VERSION "wican-gen-inhibit-diag schema 8"

NS_ :

BS_:

BU_: WICAN

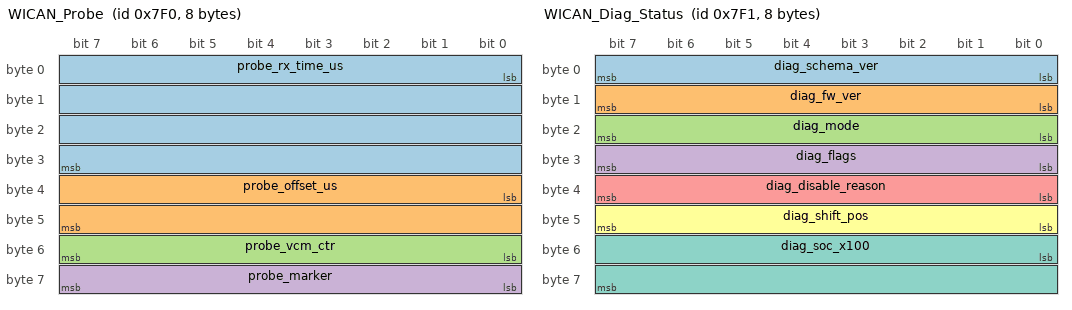
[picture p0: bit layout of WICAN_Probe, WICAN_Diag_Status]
BO_ 2032 WICAN_Probe: 8 WICAN
 SG_ probe_rx_time_us : 0|32@1+ (1,0) [0|4294967295] "us" Vector__XXX
 SG_ probe_offset_us : 32|16@1+ (1,0) [0|65535] "us" Vector__XXX
 SG_ probe_vcm_ctr : 48|8@1+ (1,0) [0|15] "" Vector__XXX
 SG_ probe_marker : 56|8@1+ (1,0) [90|90] "" Vector__XXX

BO_ 2033 WICAN_Diag_Status: 8 WICAN
 SG_ diag_schema_ver : 0|8@1+ (1,0) [0|255] "" Vector__XXX
 SG_ diag_fw_ver : 8|8@1+ (1,0) [0|255] "" Vector__XXX
 SG_ diag_mode : 16|8@1+ (1,0) [0|4] "" Vector__XXX
 SG_ diag_flags : 24|8@1+ (1,0) [0|255] "" Vector__XXX
 SG_ diag_disable_reason : 32|8@1+ (1,0) [0|2] "" Vector__XXX
 SG_ diag_shift_pos : 40|8@1+ (1,0) [0|255] "" Vector__XXX
 SG_ diag_soc_x100 : 48|16@1+ (0.01,0) [0|100] "%" Vector__XXX

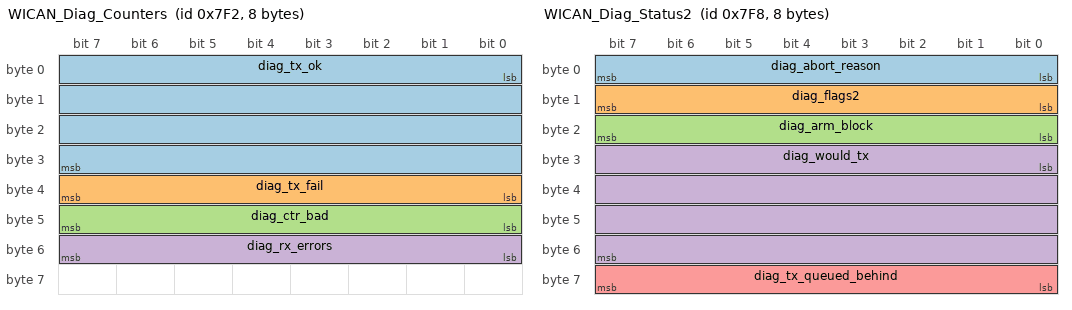
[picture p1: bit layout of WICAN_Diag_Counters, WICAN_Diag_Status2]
BO_ 2034 WICAN_Diag_Counters: 8 WICAN
 SG_ diag_tx_ok : 0|32@1+ (1,0) [0|4294967295] "" Vector__XXX
 SG_ diag_tx_fail : 32|8@1+ (1,0) [0|255] "" Vector__XXX
 SG_ diag_ctr_bad : 40|8@1+ (1,0) [0|255] "" Vector__XXX
 SG_ diag_rx_errors : 48|8@1+ (1,0) [0|255] "" Vector__XXX

BO_ 2040 WICAN_Diag_Status2: 8 WICAN
 SG_ diag_abort_reason : 0|8@1+ (1,0) [0|255] "" Vector__XXX
 SG_ diag_flags2 : 8|8@1+ (1,0) [0|255] "" Vector__XXX
 SG_ diag_arm_block : 16|8@1+ (1,0) [0|255] "" Vector__XXX
 SG_ diag_would_tx : 24|32@1+ (1,0) [0|4294967295] "" Vector__XXX
 SG_ diag_tx_queued_behind : 56|8@1+ (1,0) [0|255] "" Vector__XXX

BO_ 2041 WICAN_Diag_Skips: 8 WICAN
 SG_ diag_skips_withdrawn : 0|32@1+ (1,0) [0|4294967295] "" Vector__XXX
 SG_ diag_skips_late : 32|32@1+ (1,0) [0|4294967295] "" Vector__XXX

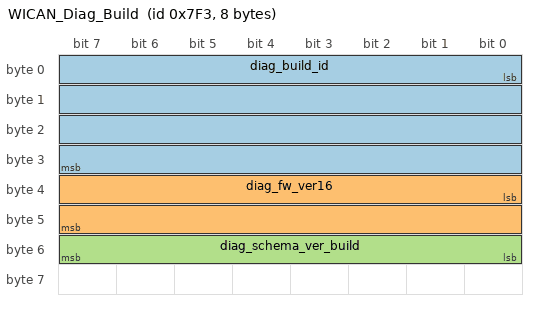
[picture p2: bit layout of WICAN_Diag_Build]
BO_ 2035 WICAN_Diag_Build: 8 WICAN
 SG_ diag_build_id : 0|32@1+ (1,0) [0|4294967295] "" Vector__XXX
 SG_ diag_fw_ver16 : 32|16@1+ (1,0) [0|65535] "" Vector__XXX
 SG_ diag_schema_ver_build : 48|8@1+ (1,0) [0|255] "" Vector__XXX

CM_ BO_ 2032 "WiCAN gen-inhibit RESPOND timing probe. 0x7F0, DLC 8, one per received 0x051 in RESPOND (diag_mode 2), due probe_offset_us after it. Not a diag frame and not versioned by diag_schema_ver. Layout published 2026-10-12 (user); source of truth: wican_diag_schema.md, section 0x7F0.";
CM_ SG_ 2032 probe_rx_time_us "The device's receive time of the 0x051 this probe answers: its own esp_timer microsecond clock, low 32 bits; wraps about every 71.6 min.";
CM_ SG_ 2032 probe_offset_us "The response delay setting the probe was scheduled with.";
CM_ SG_ 2032 probe_vcm_ctr "Rolling counter (0x051 B5 low nibble) of the most recent 0x051 received with DLC >= 6, the one this probe answers. A probe is late when this is older than the newest 0x051 counter on the wire when the probe appears.";
CM_ SG_ 2032 probe_marker "Constant 0x5A.";
CM_ BO_ 2033 "WiCAN gen-inhibit self-telemetry, STATUS. 0x7F1, DLC 8, ~1 Hz, transmitted by the WiCAN itself (not a truck ECU) so an Android/laptop log is self-documenting. 0x7F1-0x7F3 are in the 0x7Fx range nothing on the truck consumes (same rationale as the 0x7F0 timing probe). ID ALLOCATION ON THIS TRUCK: WiCAN 0x7F1-0x7F3 and 0x7F8; charge interposer 0x7F4-0x7F7 (vtrux-interposer-diag.dbc). Both devices transmit on the powertrain bus and may be fitted together, so the ranges are disjoint by agreement -- schema 4 first shipped its fourth page on 0x7F4 and had to be moved. WiCAN gained 0x7F9 (SKIPS) at schema 5, so its range is now 0x7F1-0x7F3 plus 0x7F8-0x7F9. Take the next page from 0x7FA upward and record it in both schema docs. Forward-engineered, authoritative by design; keep this DBC, the schema doc, and the firmware in lockstep via diag_schema_ver.";
CM_ BO_ 2034 "WiCAN gen-inhibit self-telemetry, COUNTERS. 0x7F2, DLC 8, ~1 Hz. Inhibit transmit totals and error counts.";
CM_ BO_ 2041 "WiCAN gen-inhibit self-telemetry, SKIPS. 0x7F9, DLC 8, added at schema 5 (spec 5.2 item 5, section 10). Skipped inhibit frames since the device was armed, split by kind. WHY THIS PAGE EXISTS: a skipped inhibit means the generator inverter acted on the VCM's real torque command for one cycle, and before schema 5 the only trace of that in a CAN log was diag_abort_reason 15 -- the trip that three skips within one second cause. An isolated skip left no trace at all, and nobody is connected to the HTTP status page during a drive. The rest of the transmit scheduler's counters are deliberately NOT here: they are on the status page only (spec section 11), because lost telemetry already shows in a CAN log as a gap in these pages themselves.";
CM_ SG_ 2041 diag_skips_withdrawn "Inhibit frames withdrawn at their deadline -- removed before reaching the wire, so the inverter never saw ours. Since arming; resets to 0 on a re-arm, so differencing across an arm boundary can step negative.";
CM_ SG_ 2041 diag_skips_late "Inhibit frames that went out late, or may have. The device cannot tell these apart: the TWAI driver reports an aborted frame and a real transmission identically, as TX_SUCCESS with msgs_to_tx falling to 0 (169 of 169 measured). Counted separately from withdrawn because a reader deciding whether our frame reached the bus needs to know which happened, and summing them would destroy exactly that. Since arming.";
CM_ BO_ 2035 "WiCAN gen-inhibit self-telemetry, BUILD. 0x7F3, DLC 8, ~1 Hz. Names the running binary by the first four bytes of its image hash (schema 8, port step 0c), for matching a log to one image file.";
CM_ SG_ 2033 diag_schema_ver "On-wire schema version. A decoder holding a different DBC version should flag a mismatch rather than trust the fields. Bump when any layout changes.";
CM_ SG_ 2033 diag_fw_ver "Behaviour/capability revision, hand-bumped when correctly parsed values must be interpreted differently or a behaviour someone would gate on changes. The name is historical; it stays, by hand, until stage (b) of the shared-code port retires it (user, 2026-10-25). diag_schema_ver governs layout and which pages exist. Rev table in the schema doc.";
CM_ SG_ 2033 diag_flags "bit0 disabled, bit1 bus_on (the CONTROLLER is running: set only while twai_get_status_info() reports TWAI_STATE_RUNNING, clear when it is stopped, bus-off or recovering, and clear when the driver is not installed -- spec 11. MEANING CHANGED AT SCHEMA 6: through schema 5 this bit reported only that the TWAI driver was installed. On the wire the change is not visible in practice: a controller that is not running transmits nothing, so a bus-off shows in a CAN log as a gap in the diag pages under either meaning. The difference shows on the status page, where on 2026-10-06 bus_on read true through 42.1 s of bus-off. The schema bump exists so that a decoder does not attach the new meaning to a schema-5 log. Check diag_schema_ver before reading it), bit2 bus_ours, bit3 autoarm_build, bit4 shutdown_suppressed (0x051 B0 = 0x10; live, non-latching, spec 6.3), bit5 inhibit_live (the spec 7 arm gate is satisfied and the inhibit is live; on its own it does not mean the inhibitor is transmitting: it stays set while armed but silent, at a key-off (bit6 clear) and during a 6.3 shutdown suppression (bit4 set); a 0x051 is sent only with bits 5 and 6 set and bits 0, 4 and 7 clear; distinct from diag_mode 3, which is only what was requested), bit6 key_on (0x592 B0 bit4 reading on AND fresh; spec 7.1 gates transmission on it, and 0 covers both a key-off and a bus with no 0x592 at all -- bit1/bit2 separate those), bit7 abort_latched (a spec 7 abort has stood the device down; it stays armed and keeps sending diag, and a key-off-to-key-on clears it).";
CM_ BO_ 2040 "WiCAN gen-inhibit self-telemetry, STATUS2. 0x7F8, DLC 8, added at schema 4 (review B1). Carries what a PASSIVE dry run needs to be readable: WHICH section 7 trip latched (diag_flags on 0x7F1 says only that one did), why the inhibit is not live, the spec 6.2 SoC-valid marker, and the would-transmit count. Appended as a fourth frame rather than repacking 0x7F1, which is full to B7 -- so a schema-3 decoder reads 0x7F1-0x7F3 unchanged and simply does not see this page.";
CM_ SG_ 2040 diag_abort_reason "Which spec 7 trip latched the inhibit off. gi_abort_t in gen_inhibit_core.h, in order -- APPEND ONLY, since reordering silently changes what every recorded log means. 14 tx_late is RETIRED (2026-09-27, spec 7 trip 7 amended): nothing sets it any more, and it is kept because captures from before that date carry it. 15 skips_3_in_1s replaced it -- a single late or withdrawn inhibit frame is now a counted skip, and three within one second trip.";
CM_ SG_ 2040 diag_arm_block "Why the inhibit is not live. 0 means the gate is satisfied. gi_block_t in gen_inhibit_core.h, append only.";
CM_ SG_ 2040 diag_flags2 "bit0 soc_valid (spec 6.2: the main contactors have reported closed and the BMS has not slept since, so 0x411 readings count), bit1 soc_since_valid (an 0x411 has arrived since the marker was set), bit2 tx_pending (an inhibit frame was outstanding when this page was built), bit3 emit_refused (a code path tried to transmit a real 0x051 from a mode that must not -- ALWAYS 0; non-zero is a firmware bug, not a bus event).";
CM_ SG_ 2040 diag_would_tx "PASSIVE (diag_mode 4) counts one of these wherever INHIBIT would have transmitted, since the last arm (reset on every arm, like diag_tx_ok, from schema 7; through schema 6 it counted since boot). Deliberately NOT folded into diag_tx_ok: a decoder that ignored diag_mode would otherwise read a dry run as a drive in which the device transmitted thousands of times. The two are mutually exclusive by mode, which is a property worth being able to check.";
CM_ SG_ 2040 diag_tx_queued_behind "Spec 5's hazard, counted: inhibit frames queued into the controller behind a frame of ours that had not finished. Saturates at 255. Any non-zero value on the bench is the thing the full-replay run exists to measure.";
CM_ SG_ 2035 diag_build_id "The first four bytes of the running image's image hash: the ELF SHA-256 ESP-IDF embeds in the app descriptor (shared/tools R1), read at run time. Packed as the charge interposer's 0x7F7 build id: hash byte 0 most significant, sent little-endian, so this unsigned value printed as eight hex digits reads as the hash's first four bytes in order. Look it up in the release build records and the bench run records, which name each image by its full hash: no match is unknown, two matches are ambiguous, never guessed. Schema 8 (port step 0c, user 2026-10-19 and 2026-10-25); through schema 7 these bytes were diag_git_hash, an FNV-1a hash of the build's name.";

BA_DEF_ "DiagSchemaVersion" INT 0 255;
BA_DEF_ "DiagSchemaHash" STRING ;
BA_DEF_DEF_ "DiagSchemaVersion" 0;
BA_DEF_DEF_ "DiagSchemaHash" "";
BA_ "DiagSchemaVersion" 8;
BA_ "DiagSchemaHash" "00401e953c405902";

VAL_ 2033 diag_mode 0 "OFF" 1 "OBSERVE" 2 "RESPOND" 3 "INHIBIT" 4 "PASSIVE";
VAL_ 2040 diag_abort_reason 0 "none" 1 "tx_failed" 2 "vcm_fault" 3 "bus_lost" 4 "inverter_lost" 5 "engine_turning" 6 "error_rate" 7 "stale_soc" 8 "stale_contactor" 9 "stale_fault" 10 "stale_shift" 11 "stale_rpm" 12 "short_vcm_frame" 13 "tx_not_queued" 14 "tx_late_retired_2026_09_27" 15 "skips_3_in_1s";
VAL_ 2040 diag_arm_block 0 "none" 1 "not_armed" 2 "gate_not_evaluated" 3 "no_fresh_cmd" 4 "vcm_fault" 5 "gen_running" 6 "vcm_req_engine" 7 "vcm_torque" 8 "shutdown_cmd" 9 "no_soc_valid" 10 "contactors_open" 11 "no_fresh_fault" 12 "no_fresh_shift" 13 "disabled" 14 "aborted" 15 "rx_not_drained";
VAL_ 2033 diag_disable_reason 0 "none" 1 "m_mode" 2 "low_soc";
VAL_ 2033 diag_shift_pos 0 "Park" 1 "Reverse" 2 "Neutral" 3 "Drive" 4 "Manual_generator_mode" 255 "unseen";
